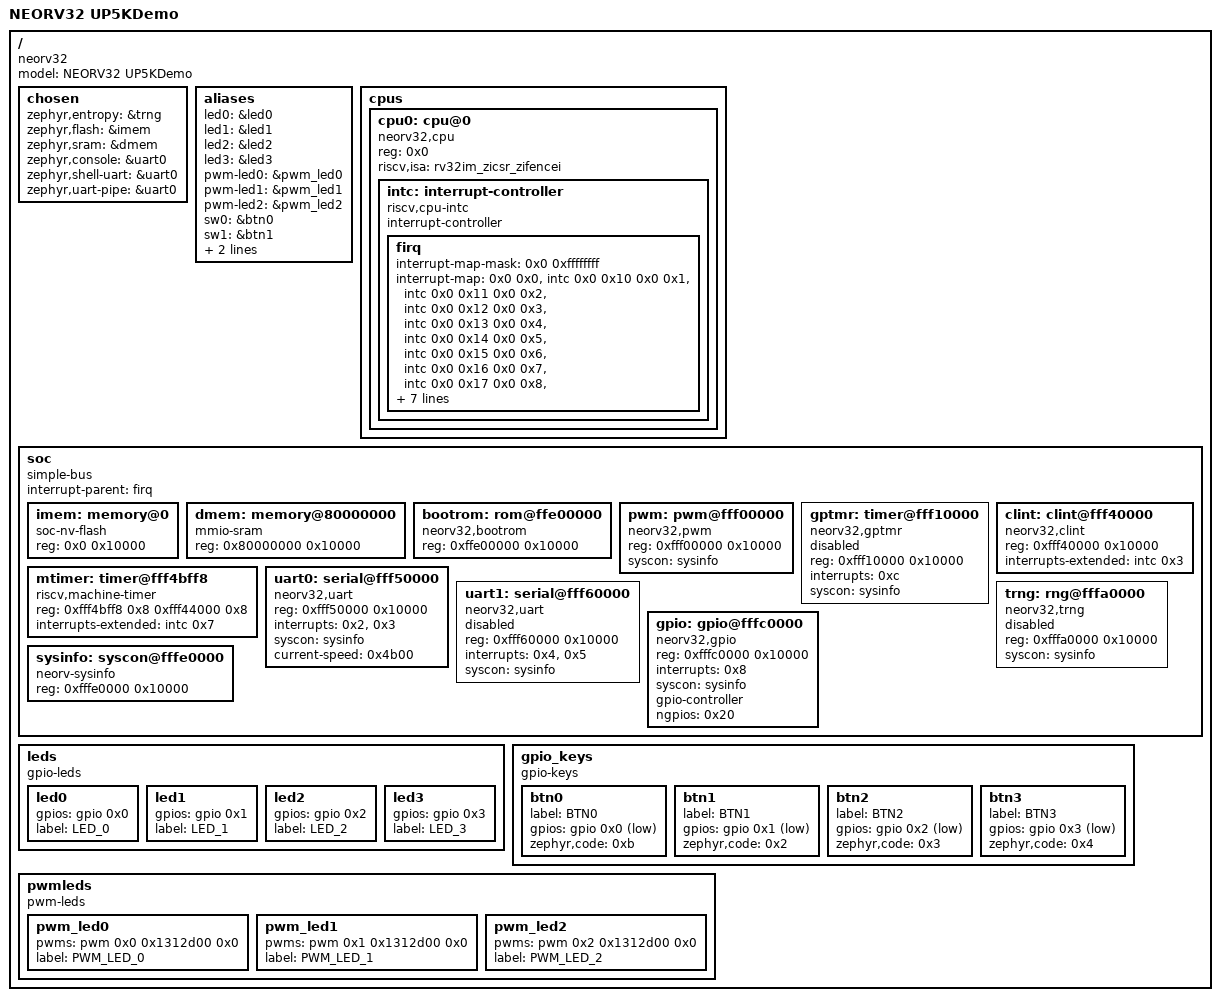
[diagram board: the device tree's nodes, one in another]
/dts-v1/;

/* node '/' defined in zephyr/dts/common/skeleton.dtsi:9 */
/ {
	#address-cells = < 0x1 >;   /* in zephyr/dts/common/skeleton.dtsi:10 */
	#size-cells = < 0x1 >;      /* in zephyr/dts/common/skeleton.dtsi:11 */
	model = "NEORV32 UP5KDemo"; /* in zephyr/boards/others/neorv32/neorv32_neorv32_up5kdemo.dts:14 */
	compatible = "neorv32";     /* in zephyr/boards/others/neorv32/neorv32_neorv32_up5kdemo.dts:15 */

	/* node '/chosen' defined in zephyr/dts/common/skeleton.dtsi:13 */
	chosen {
		zephyr,entropy = &trng;     /* in zephyr/dts/riscv/neorv32.dtsi:15 */
		zephyr,flash = &imem;       /* in zephyr/boards/others/neorv32/neorv32_neorv32_up5kdemo.dts:32 */
		zephyr,sram = &dmem;        /* in zephyr/boards/others/neorv32/neorv32_neorv32_up5kdemo.dts:33 */
		zephyr,console = &uart0;    /* in zephyr/boards/others/neorv32/neorv32_neorv32_up5kdemo.dts:34 */
		zephyr,shell-uart = &uart0; /* in zephyr/boards/others/neorv32/neorv32_neorv32_up5kdemo.dts:35 */
		zephyr,uart-pipe = &uart0;  /* in zephyr/boards/others/neorv32/neorv32_neorv32_up5kdemo.dts:36 */
	};

	/* node '/aliases' defined in zephyr/dts/common/skeleton.dtsi:15 */
	aliases {
		led0 = &led0;         /* in zephyr/boards/others/neorv32/neorv32_neorv32_up5kdemo.dts:18 */
		led1 = &led1;         /* in zephyr/boards/others/neorv32/neorv32_neorv32_up5kdemo.dts:19 */
		led2 = &led2;         /* in zephyr/boards/others/neorv32/neorv32_neorv32_up5kdemo.dts:20 */
		led3 = &led3;         /* in zephyr/boards/others/neorv32/neorv32_neorv32_up5kdemo.dts:21 */
		pwm-led0 = &pwm_led0; /* in zephyr/boards/others/neorv32/neorv32_neorv32_up5kdemo.dts:22 */
		pwm-led1 = &pwm_led1; /* in zephyr/boards/others/neorv32/neorv32_neorv32_up5kdemo.dts:23 */
		pwm-led2 = &pwm_led2; /* in zephyr/boards/others/neorv32/neorv32_neorv32_up5kdemo.dts:24 */
		sw0 = &btn0;          /* in zephyr/boards/others/neorv32/neorv32_neorv32_up5kdemo.dts:25 */
		sw1 = &btn1;          /* in zephyr/boards/others/neorv32/neorv32_neorv32_up5kdemo.dts:26 */
		sw3 = &btn2;          /* in zephyr/boards/others/neorv32/neorv32_neorv32_up5kdemo.dts:27 */
		sw4 = &btn3;          /* in zephyr/boards/others/neorv32/neorv32_neorv32_up5kdemo.dts:28 */
	};

	/* node '/cpus' defined in zephyr/dts/riscv/neorv32.dtsi:18 */
	cpus {
		#address-cells = < 0x1 >; /* in zephyr/dts/riscv/neorv32.dtsi:19 */
		#size-cells = < 0x0 >;    /* in zephyr/dts/riscv/neorv32.dtsi:20 */

		/* node '/cpus/cpu@0' defined in zephyr/dts/riscv/neorv32.dtsi:22 */
		cpu0: cpu@0 {
			compatible = "neorv32,cpu",
			             "riscv";                /* in zephyr/dts/riscv/neorv32.dtsi:23 */
			reg = < 0x0 >;                       /* in zephyr/dts/riscv/neorv32.dtsi:24 */
			device_type = "cpu";                 /* in zephyr/dts/riscv/neorv32.dtsi:25 */
			riscv,isa = "rv32im_zicsr_zifencei"; /* in zephyr/boards/others/neorv32/neorv32_neorv32_up5kdemo.dts:112 */

			/* node '/cpus/cpu@0/interrupt-controller' defined in zephyr/dts/riscv/neorv32.dtsi:27 */
			intc: interrupt-controller {
				compatible = "riscv,cpu-intc"; /* in zephyr/dts/riscv/neorv32.dtsi:28 */
				interrupt-controller;          /* in zephyr/dts/riscv/neorv32.dtsi:29 */
				#address-cells = < 0x1 >;      /* in zephyr/dts/riscv/neorv32.dtsi:30 */
				#interrupt-cells = < 0x1 >;    /* in zephyr/dts/riscv/neorv32.dtsi:31 */
				phandle = < 0x1 >;             /* in zephyr/dts/riscv/neorv32.dtsi:36 */

				/* node '/cpus/cpu@0/interrupt-controller/firq' defined in zephyr/dts/riscv/neorv32.dtsi:33 */
				firq: firq {
					#address-cells = < 0x1 >;                                                                            /* in zephyr/dts/riscv/neorv32.dtsi:34 */
					interrupt-map-mask = < 0x0 0xffffffff >;                                                             /* in zephyr/dts/riscv/neorv32.dtsi:35 */
					interrupt-map = < 0x0 0x0 &intc 0x0 0x10 0x0 0x1 &intc 0x0 0x11 0x0 0x2 &intc 0x0 0x12 0x0 0x3 &intc
					                  0x0 0x13 0x0 0x4 &intc 0x0 0x14 0x0 0x5 &intc 0x0 0x15 0x0 0x6 &intc 0x0 0x16 0x0
					                  0x7 &intc 0x0 0x17 0x0 0x8 &intc 0x0 0x18 0x0 0x9 &intc 0x0 0x19 0x0 0xa &intc 0x0
					                  0x1a 0x0 0xb &intc 0x0 0x1b 0x0 0xc &intc 0x0 0x1c 0x0 0xd &intc 0x0 0x1d 0x0 0xe
					                  &intc 0x0 0x1e 0x0 0xf &intc 0x0 0x1f >;                                           /* in zephyr/dts/riscv/neorv32.dtsi:36 */
					#interrupt-cells = < 0x1 >;                                                                          /* in zephyr/dts/riscv/neorv32.dtsi:52 */
					phandle = < 0x2 >;                                                                                   /* in zephyr/dts/riscv/neorv32.dtsi:60 */
				};
			};
		};
	};

	/* node '/soc' defined in zephyr/dts/riscv/neorv32.dtsi:58 */
	soc {
		compatible = "simple-bus";    /* in zephyr/dts/riscv/neorv32.dtsi:59 */
		interrupt-parent = < &firq >; /* in zephyr/dts/riscv/neorv32.dtsi:60 */
		#address-cells = < 0x1 >;     /* in zephyr/dts/riscv/neorv32.dtsi:61 */
		#size-cells = < 0x1 >;        /* in zephyr/dts/riscv/neorv32.dtsi:62 */
		ranges;                       /* in zephyr/dts/riscv/neorv32.dtsi:63 */

		/* node '/soc/memory@0' defined in zephyr/dts/riscv/neorv32.dtsi:65 */
		imem: memory@0 {
			compatible = "soc-nv-flash",
			             "mmio-sram";    /* in zephyr/dts/riscv/neorv32.dtsi:66 */
			status = "okay";             /* in zephyr/boards/others/neorv32/neorv32_neorv32_up5kdemo.dts:120 */
			reg = < 0x0 0x10000 >;       /* in zephyr/boards/others/neorv32/neorv32_neorv32_up5kdemo.dts:121 */
		};

		/* node '/soc/memory@80000000' defined in zephyr/dts/riscv/neorv32.dtsi:70 */
		dmem: memory@80000000 {
			compatible = "mmio-sram";     /* in zephyr/dts/riscv/neorv32.dtsi:71 */
			status = "okay";              /* in zephyr/boards/others/neorv32/neorv32_neorv32_up5kdemo.dts:125 */
			reg = < 0x80000000 0x10000 >; /* in zephyr/boards/others/neorv32/neorv32_neorv32_up5kdemo.dts:126 */
		};

		/* node '/soc/rom@ffe00000' defined in zephyr/dts/riscv/neorv32.dtsi:75 */
		bootrom: rom@ffe00000 {
			compatible = "neorv32,bootrom",
			             "mmio-sram";       /* in zephyr/dts/riscv/neorv32.dtsi:76 */
			reg = < 0xffe00000 0x10000 >;   /* in zephyr/dts/riscv/neorv32.dtsi:78 */
			status = "okay";                /* in zephyr/boards/others/neorv32/neorv32_neorv32_up5kdemo.dts:116 */
		};

		/* node '/soc/pwm@fff00000' defined in zephyr/dts/riscv/neorv32.dtsi:81 */
		pwm: pwm@fff00000 {
			compatible = "neorv32,pwm";   /* in zephyr/dts/riscv/neorv32.dtsi:82 */
			reg = < 0xfff00000 0x10000 >; /* in zephyr/dts/riscv/neorv32.dtsi:84 */
			syscon = < &sysinfo >;        /* in zephyr/dts/riscv/neorv32.dtsi:85 */
			#pwm-cells = < 0x3 >;         /* in zephyr/dts/riscv/neorv32.dtsi:86 */
			status = "okay";              /* in zephyr/boards/others/neorv32/neorv32_neorv32_up5kdemo.dts:148 */
			phandle = < 0x5 >;            /* in zephyr/boards/others/neorv32/neorv32_neorv32_up5kdemo.dts:95 */
		};

		/* node '/soc/timer@fff10000' defined in zephyr/dts/riscv/neorv32.dtsi:89 */
		gptmr: timer@fff10000 {
			compatible = "neorv32,gptmr"; /* in zephyr/dts/riscv/neorv32.dtsi:90 */
			status = "disabled";          /* in zephyr/dts/riscv/neorv32.dtsi:91 */
			reg = < 0xfff10000 0x10000 >; /* in zephyr/dts/riscv/neorv32.dtsi:92 */
			interrupts = < 0xc >;         /* in zephyr/dts/riscv/neorv32.dtsi:93 */
			syscon = < &sysinfo >;        /* in zephyr/dts/riscv/neorv32.dtsi:94 */
		};

		/* node '/soc/clint@fff40000' defined in zephyr/dts/riscv/neorv32.dtsi:97 */
		clint: clint@fff40000 {
			compatible = "neorv32,clint",
			             "sifive,clint0";        /* in zephyr/dts/riscv/neorv32.dtsi:98 */
			reg = < 0xfff40000 0x10000 >;        /* in zephyr/dts/riscv/neorv32.dtsi:100 */
			interrupts-extended = < &intc 0x3 >; /* in zephyr/dts/riscv/neorv32.dtsi:101 */
			status = "okay";                     /* in zephyr/boards/others/neorv32/neorv32_neorv32_up5kdemo.dts:130 */
		};

		/* node '/soc/timer@fff4bff8' defined in zephyr/dts/riscv/neorv32.dtsi:104 */
		mtimer: timer@fff4bff8 {
			compatible = "riscv,machine-timer";      /* in zephyr/dts/riscv/neorv32.dtsi:105 */
			reg = < 0xfff4bff8 0x8 0xfff44000 0x8 >; /* in zephyr/dts/riscv/neorv32.dtsi:107 */
			reg-names = "mtime",
			            "mtimecmp";                  /* in zephyr/dts/riscv/neorv32.dtsi:108 */
			interrupts-extended = < &intc 0x7 >;     /* in zephyr/dts/riscv/neorv32.dtsi:109 */
			status = "okay";                         /* in zephyr/boards/others/neorv32/neorv32_neorv32_up5kdemo.dts:134 */
		};

		/* node '/soc/serial@fff50000' defined in zephyr/dts/riscv/neorv32.dtsi:112 */
		uart0: serial@fff50000 {
			compatible = "neorv32,uart";  /* in zephyr/dts/riscv/neorv32.dtsi:113 */
			reg = < 0xfff50000 0x10000 >; /* in zephyr/dts/riscv/neorv32.dtsi:115 */
			interrupts = < 0x2 >,
			             < 0x3 >;         /* in zephyr/dts/riscv/neorv32.dtsi:116 */
			interrupt-names = "RX",
			                  "TX";       /* in zephyr/dts/riscv/neorv32.dtsi:117 */
			syscon = < &sysinfo >;        /* in zephyr/dts/riscv/neorv32.dtsi:118 */
			status = "okay";              /* in zephyr/boards/others/neorv32/neorv32_neorv32_up5kdemo.dts:138 */
			current-speed = < 0x4b00 >;   /* in zephyr/boards/others/neorv32/neorv32_neorv32_up5kdemo.dts:139 */
		};

		/* node '/soc/serial@fff60000' defined in zephyr/dts/riscv/neorv32.dtsi:121 */
		uart1: serial@fff60000 {
			compatible = "neorv32,uart";  /* in zephyr/dts/riscv/neorv32.dtsi:122 */
			status = "disabled";          /* in zephyr/dts/riscv/neorv32.dtsi:123 */
			reg = < 0xfff60000 0x10000 >; /* in zephyr/dts/riscv/neorv32.dtsi:124 */
			interrupts = < 0x4 >,
			             < 0x5 >;         /* in zephyr/dts/riscv/neorv32.dtsi:125 */
			interrupt-names = "RX",
			                  "TX";       /* in zephyr/dts/riscv/neorv32.dtsi:126 */
			syscon = < &sysinfo >;        /* in zephyr/dts/riscv/neorv32.dtsi:127 */
		};

		/* node '/soc/rng@fffa0000' defined in zephyr/dts/riscv/neorv32.dtsi:130 */
		trng: rng@fffa0000 {
			compatible = "neorv32,trng";  /* in zephyr/dts/riscv/neorv32.dtsi:131 */
			status = "disabled";          /* in zephyr/dts/riscv/neorv32.dtsi:132 */
			reg = < 0xfffa0000 0x10000 >; /* in zephyr/dts/riscv/neorv32.dtsi:133 */
			syscon = < &sysinfo >;        /* in zephyr/dts/riscv/neorv32.dtsi:134 */
		};

		/* node '/soc/gpio@fffc0000' defined in zephyr/dts/riscv/neorv32.dtsi:137 */
		gpio: gpio@fffc0000 {
			compatible = "neorv32,gpio";  /* in zephyr/dts/riscv/neorv32.dtsi:138 */
			reg = < 0xfffc0000 0x10000 >; /* in zephyr/dts/riscv/neorv32.dtsi:140 */
			interrupts = < 0x8 >;         /* in zephyr/dts/riscv/neorv32.dtsi:141 */
			syscon = < &sysinfo >;        /* in zephyr/dts/riscv/neorv32.dtsi:142 */
			gpio-controller;              /* in zephyr/dts/riscv/neorv32.dtsi:143 */
			#gpio-cells = < 0x2 >;        /* in zephyr/dts/riscv/neorv32.dtsi:145 */
			status = "okay";              /* in zephyr/boards/others/neorv32/neorv32_neorv32_up5kdemo.dts:143 */
			ngpios = < 0x20 >;            /* in zephyr/boards/others/neorv32/neorv32_neorv32_up5kdemo.dts:144 */
			phandle = < 0x4 >;            /* in zephyr/boards/others/neorv32/neorv32_neorv32_up5kdemo.dts:43 */
		};

		/* node '/soc/syscon@fffe0000' defined in zephyr/dts/riscv/neorv32.dtsi:148 */
		sysinfo: syscon@fffe0000 {
			compatible = "neorv-sysinfo",
			             "syscon";        /* in zephyr/dts/riscv/neorv32.dtsi:149 */
			status = "okay";              /* in zephyr/dts/riscv/neorv32.dtsi:150 */
			reg = < 0xfffe0000 0x10000 >; /* in zephyr/dts/riscv/neorv32.dtsi:151 */
			phandle = < 0x3 >;            /* in zephyr/dts/riscv/neorv32.dtsi:85 */
		};
	};

	/* node '/leds' defined in zephyr/boards/others/neorv32/neorv32_neorv32_up5kdemo.dts:39 */
	leds {
		compatible = "gpio-leds"; /* in zephyr/boards/others/neorv32/neorv32_neorv32_up5kdemo.dts:40 */

		/* node '/leds/led0' defined in zephyr/boards/others/neorv32/neorv32_neorv32_up5kdemo.dts:42 */
		led0: led0 {
			gpios = < &gpio 0x0 0x0 >; /* in zephyr/boards/others/neorv32/neorv32_neorv32_up5kdemo.dts:43 */
			label = "LED_0";           /* in zephyr/boards/others/neorv32/neorv32_neorv32_up5kdemo.dts:44 */
		};

		/* node '/leds/led1' defined in zephyr/boards/others/neorv32/neorv32_neorv32_up5kdemo.dts:47 */
		led1: led1 {
			gpios = < &gpio 0x1 0x0 >; /* in zephyr/boards/others/neorv32/neorv32_neorv32_up5kdemo.dts:48 */
			label = "LED_1";           /* in zephyr/boards/others/neorv32/neorv32_neorv32_up5kdemo.dts:49 */
		};

		/* node '/leds/led2' defined in zephyr/boards/others/neorv32/neorv32_neorv32_up5kdemo.dts:52 */
		led2: led2 {
			gpios = < &gpio 0x2 0x0 >; /* in zephyr/boards/others/neorv32/neorv32_neorv32_up5kdemo.dts:53 */
			label = "LED_2";           /* in zephyr/boards/others/neorv32/neorv32_neorv32_up5kdemo.dts:54 */
		};

		/* node '/leds/led3' defined in zephyr/boards/others/neorv32/neorv32_neorv32_up5kdemo.dts:57 */
		led3: led3 {
			gpios = < &gpio 0x3 0x0 >; /* in zephyr/boards/others/neorv32/neorv32_neorv32_up5kdemo.dts:58 */
			label = "LED_3";           /* in zephyr/boards/others/neorv32/neorv32_neorv32_up5kdemo.dts:59 */
		};
	};

	/* node '/gpio_keys' defined in zephyr/boards/others/neorv32/neorv32_neorv32_up5kdemo.dts:63 */
	gpio_keys {
		compatible = "gpio-keys"; /* in zephyr/boards/others/neorv32/neorv32_neorv32_up5kdemo.dts:64 */

		/* node '/gpio_keys/btn0' defined in zephyr/boards/others/neorv32/neorv32_neorv32_up5kdemo.dts:66 */
		btn0: btn0 {
			label = "BTN0";            /* in zephyr/boards/others/neorv32/neorv32_neorv32_up5kdemo.dts:67 */
			gpios = < &gpio 0x0 0x1 >; /* in zephyr/boards/others/neorv32/neorv32_neorv32_up5kdemo.dts:68 */
			zephyr,code = < 0xb >;     /* in zephyr/boards/others/neorv32/neorv32_neorv32_up5kdemo.dts:69 */
		};

		/* node '/gpio_keys/btn1' defined in zephyr/boards/others/neorv32/neorv32_neorv32_up5kdemo.dts:72 */
		btn1: btn1 {
			label = "BTN1";            /* in zephyr/boards/others/neorv32/neorv32_neorv32_up5kdemo.dts:73 */
			gpios = < &gpio 0x1 0x1 >; /* in zephyr/boards/others/neorv32/neorv32_neorv32_up5kdemo.dts:74 */
			zephyr,code = < 0x2 >;     /* in zephyr/boards/others/neorv32/neorv32_neorv32_up5kdemo.dts:75 */
		};

		/* node '/gpio_keys/btn2' defined in zephyr/boards/others/neorv32/neorv32_neorv32_up5kdemo.dts:78 */
		btn2: btn2 {
			label = "BTN2";            /* in zephyr/boards/others/neorv32/neorv32_neorv32_up5kdemo.dts:79 */
			gpios = < &gpio 0x2 0x1 >; /* in zephyr/boards/others/neorv32/neorv32_neorv32_up5kdemo.dts:80 */
			zephyr,code = < 0x3 >;     /* in zephyr/boards/others/neorv32/neorv32_neorv32_up5kdemo.dts:81 */
		};

		/* node '/gpio_keys/btn3' defined in zephyr/boards/others/neorv32/neorv32_neorv32_up5kdemo.dts:84 */
		btn3: btn3 {
			label = "BTN3";            /* in zephyr/boards/others/neorv32/neorv32_neorv32_up5kdemo.dts:85 */
			gpios = < &gpio 0x3 0x1 >; /* in zephyr/boards/others/neorv32/neorv32_neorv32_up5kdemo.dts:86 */
			zephyr,code = < 0x4 >;     /* in zephyr/boards/others/neorv32/neorv32_neorv32_up5kdemo.dts:87 */
		};
	};

	/* node '/pwmleds' defined in zephyr/boards/others/neorv32/neorv32_neorv32_up5kdemo.dts:91 */
	pwmleds {
		compatible = "pwm-leds"; /* in zephyr/boards/others/neorv32/neorv32_neorv32_up5kdemo.dts:92 */

		/* node '/pwmleds/pwm_led0' defined in zephyr/boards/others/neorv32/neorv32_neorv32_up5kdemo.dts:94 */
		pwm_led0: pwm_led0 {
			pwms = < &pwm 0x0 0x1312d00 0x0 >; /* in zephyr/boards/others/neorv32/neorv32_neorv32_up5kdemo.dts:95 */
			label = "PWM_LED_0";               /* in zephyr/boards/others/neorv32/neorv32_neorv32_up5kdemo.dts:96 */
		};

		/* node '/pwmleds/pwm_led1' defined in zephyr/boards/others/neorv32/neorv32_neorv32_up5kdemo.dts:99 */
		pwm_led1: pwm_led1 {
			pwms = < &pwm 0x1 0x1312d00 0x0 >; /* in zephyr/boards/others/neorv32/neorv32_neorv32_up5kdemo.dts:100 */
			label = "PWM_LED_1";               /* in zephyr/boards/others/neorv32/neorv32_neorv32_up5kdemo.dts:101 */
		};

		/* node '/pwmleds/pwm_led2' defined in zephyr/boards/others/neorv32/neorv32_neorv32_up5kdemo.dts:104 */
		pwm_led2: pwm_led2 {
			pwms = < &pwm 0x2 0x1312d00 0x0 >; /* in zephyr/boards/others/neorv32/neorv32_neorv32_up5kdemo.dts:105 */
			label = "PWM_LED_2";               /* in zephyr/boards/others/neorv32/neorv32_neorv32_up5kdemo.dts:106 */
		};
	};
};
